# STM32H503 register map
File version: 1.5
CPU: CM33 r0p0, little endian, MPU, FPU, 4 interrupt priority bits
Registers are 32-bit, read-write, reset 0x0 unless marked. A register's access mark holds for its fields unless they carry their own. Offsets are from the block's base; [hi:lo] are bit positions.

## CRC — Cyclic redundancy check calculation unit
Base 0x40023000
0x00 DR reset 0xFFFFFFFF — CRC data register
  [31:0] DR — Data register bits This register is used to write new data to the CRC calculator. It holds the previous CRC calculation result when it is read. If the data size is less than 32 bits, the least significant bits are used to write/read the correct value.
0x00 DR8 8-bit reset 0xFF (alternate view of DR) — Data register - byte sized
  [7:0] DR8 — Data register bits
0x00 DR16 16-bit reset 0xFFFF (alternate view of DR) — Data register - half-word sized
  [15:0] DR16 — Data register bits
0x04 IDR — CRC independent data register
  [31:0] IDR — General-purpose 32-bit data register bits These bits can be used as a temporary storage location for four bytes. This register is not affected by CRC resets generated by the RESET bit in the CRC_CR register
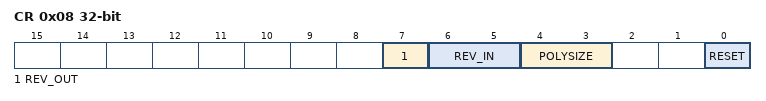
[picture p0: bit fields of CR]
0x08 CR — CRC control register
  [7] REV_OUT — Reverse output data This bit controls the reversal of the bit order of the output data.
    0=Normal (Bit order not affected); 1=Reversed (Bit reversed output)
  [6:5] REV_IN — Reverse input data These bits control the reversal of the bit order of the input data
    0=Normal (Bit order not affected); 1=Byte (Bit reversal done by byte); 2=HalfWord (Bit reversal done by half-word); 3=Word (Bit reversal done by word)
  [4:3] POLYSIZE — Polynomial size These bits control the size of the polynomial.
    0=32-bit polynomial; 1=16-bit polynomial; 2=8-bit polynomial; 3=7-bit polynomial
  [0] RESET — RESET bit This bit is set by software to reset the CRC calculation unit and set the data register to the value stored in the CRC_INIT register. This bit can only be set, it is automatically cleared by hardware
    on write: 1=Resets the CRC calculation unit and sets the data register to 0xFFFF FFFF
0x10 INIT reset 0xFFFFFFFF — CRC initial value
  [31:0] INIT — Programmable initial CRC value This register is used to write the CRC initial value.
0x14 POL reset 0x4C11DB7 — CRC polynomial
  [31:0] POL — Programmable polynomial This register is used to write the coefficients of the polynomial to be used for CRC calculation. If the polynomial size is less than 32 bits, the least significant bits have to be used to program the correct value.

## ICACHE — Instruction cache
Base 0x40030400
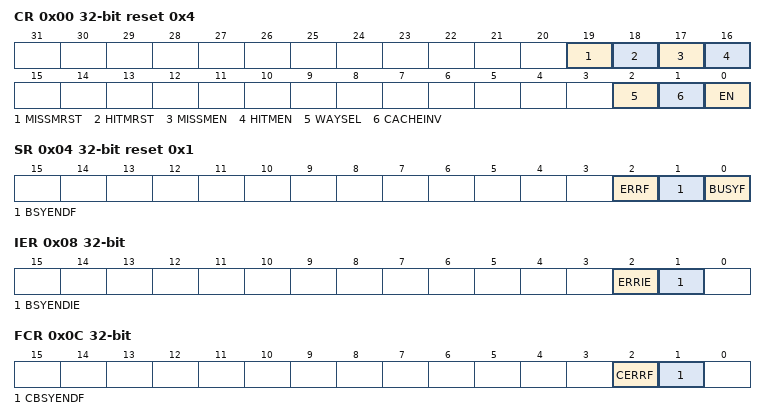
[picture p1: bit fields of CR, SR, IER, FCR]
0x00 CR access per field reset 0x4 — ICACHE control register
  [19] MISSMRST rw — miss monitor reset
  [18] HITMRST rw — hit monitor reset
  [17] MISSMEN rw — miss monitor enable
  [16] HITMEN rw — hit monitor enable
  [2] WAYSEL rw — cache associativity mode selection This bit allows user to choose ICACHE set-associativity. It can be written by software only when cache is disabled (EN = 0).
  [1] CACHEINV wo — cache invalidation Set by software and cleared by hardware when the BUSYF flag is set (during cache maintenance operation). Writing 0 has no effect.
  [0] EN rw — enable
0x04 SR ro reset 0x1 — ICACHE status register
  [2] ERRF — cache error flag
  [1] BSYENDF — busy end flag
  [0] BUSYF — busy flag
0x08 IER — ICACHE interrupt enable register
  [2] ERRIE — interrupt enable on cache error Set by software to enable an interrupt generation in case of cache functional error (cacheable write access)
  [1] BSYENDIE — interrupt enable on busy end Set by software to enable an interrupt generation at the end of a cache invalidate operation.
0x0C FCR wo — ICACHE flag clear register
  [2] CERRF — clear cache error flag Set by software.
  [1] CBSYENDF — clear busy end flag Set by software.
0x10 HMONR ro — ICACHE hit monitor register
  [31:0] HITMON — cache hit monitor counter
0x14 MMONR ro — ICACHE miss monitor register
  [15:0] MISSMON — cache miss monitor counter
